# STM32H563 register map
File version: 1.6
CPU: CM33 r0p0, little endian, MPU, FPU, 4 interrupt priority bits
Registers are 32-bit, read-write, reset 0x0 unless marked. A register's access mark holds for its fields unless they carry their own. Offsets are from the block's base; [hi:lo] are bit positions.

## DCACHE — Data cache
Base 0x40031400
Same registers: SEC_DCACHE 0x50031400
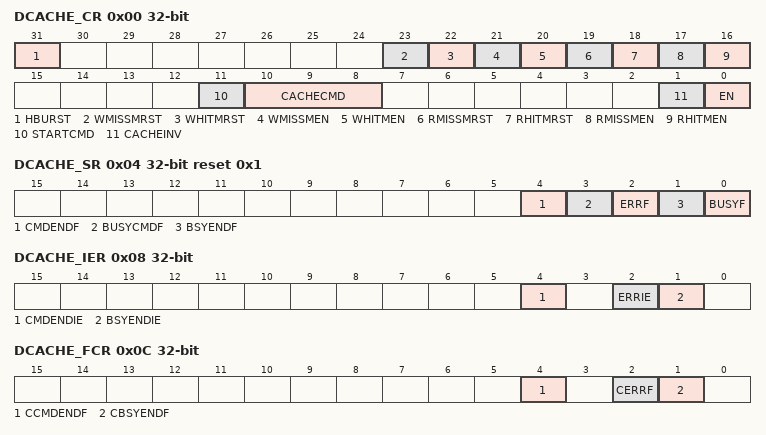
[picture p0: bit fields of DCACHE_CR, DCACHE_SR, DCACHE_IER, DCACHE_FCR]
0x00 DCACHE_CR access per field — DCACHE control register
  [31] HBURST rw — output burst type for cache master port read accesses Write access is always done in INCR burst type.
    0=WRAP; 1=INCR
  [23] WMISSMRST rw — write-miss monitor reset
    0=no effect; 1=reset cache write-miss monitor
  [22] WHITMRST rw — write-hit monitor reset
    0=no effect; 1=reset cache write-hit monitor
  [21] WMISSMEN rw — write-miss monitor enable
    0=cache write-miss monitor switched off. Stopping the monitor does not reset it.; 1=cache write-miss monitor enabled
  [20] WHITMEN rw — write-hit monitor enable
    0=cache write-hit monitor switched off. Stopping the monitor does not reset it.; 1=cache write-hit monitor enabled
  [19] RMISSMRST rw — read-miss monitor reset
    0=no effect; 1=reset cache read-miss monitor
  [18] RHITMRST rw — read-hit monitor reset
    0=no effect; 1=reset cache read-hit monitor
  [17] RMISSMEN rw — read-miss monitor enable
    0=cache read-miss monitor switched off. Stopping the monitor does not reset it.; 1=cache read-miss monitor enabled
  [16] RHITMEN rw — read-hit monitor enable
    0=cache read-hit monitor switched off. Stopping the monitor does not reset it.; 1=cache read-hit monitor enabled
  [11] STARTCMD wo — starts maintenance command (maintenance operation defined in CACHECMD). Can be set by software, only when EN = 1, BUSYCMDF = 0, BUSYF = 0 and CACHECMD = 0b001, 0b010 or 0b011. Cleared by hardware when the BUSYCMDF flag is set (during cache maintenance operation). Writing 0 has no effect.
    0=command operation (cache maintenance) finished; 1=start maintenance command (cache maintenance)
  [10:8] CACHECMD rw — cache command maintenance operation (cleans and/or invalidates an address range) Can be set and cleared by software, only when no maintenance command is ongoing (BUSYCMDF = 0). others: reserved
    0=no operation; 1=clean range; 2=invalidate range; 3=clean and invalidate range
  [1] CACHEINV wo — full cache invalidation Can be set by software, only when EN = 1. Cleared by hardware when the BUSYF flag is set (during full cache invalidation operation). Writing 0 has no effect.
    0=no effect; 1=invalidate entire cache (all cache lines valid bit = 0)
  [0] EN rw — enable
    0=cache disabled; 1=cache enabled
0x04 DCACHE_SR ro reset 0x1 — DCACHE status register
  [4] CMDENDF — command end flag Cleared by writing DCACHE_FCR.CCMDENDF = 1.
    0=cache busy or in idle; 1=CACHECMD command finished
  [3] BUSYCMDF — command busy flag
    0=cache not busy on a CACHECMD command; 1=cache busy on a CACHECMD command (clean and/or invalidate an address range)
  [2] ERRF — cache error flag Cleared by writing DCACHE_FCR.CERRF = 1.
    0=no error; 1=an error occurred during the operation (eviction or clean operation write-back error)
  [1] BSYENDF — full invalidate busy end flag Cleared by writing DCACHE_FCR.CBSYENDF = 1.
    0=cache busy or in idle; 1=full invalidate CACHEINV operation finished
  [0] BUSYF — full invalidate busy flag
    0=cache not busy on a CACHEINV operation; 1=cache executing a full invalidate CACHEINV operation
0x08 DCACHE_IER — DCACHE interrupt enable register
  [4] CMDENDIE — interrupt enable on command end Set by software to enable an interrupt generation at the end of a cache command (clean and/or invalidate an address range)
    0=interrupt disabled on command end; 1=interrupt enabled on command end
  [2] ERRIE — interrupt enable on cache error Set by software to enable an interrupt generation in case of cache functional error (eviction or clean operation write-back error)
    0=interrupt disabled on error; 1=interrupt enabled on error
  [1] BSYENDIE — interrupt enable on busy end Set by SW to enable an interrupt generation at the end of a cache full invalidate operation.
    0=Interrupt disabled on busy end; 1=Interrupt enabled on busy end
0x0C DCACHE_FCR wo — DCACHE flag clear register
  [4] CCMDENDF — clear command end flag Set by software.
    0=no effect; 1=clears CMDENDF flag in DCACHE_SR
  [2] CERRF — clear cache error flag Set by software.
    0=no effect; 1=clears ERRF flag in DCACHE_SR
  [1] CBSYENDF — clear full invalidate busy end flag Set by software.
    0=no effect; 1=clears BSYENDF flag in DCACHE_SR
0x10 DCACHE_RHMONR ro — DCACHE read-hit monitor register
  [31:0] RHITMON — cache read-hit monitor counter
0x14 DCACHE_RMMONR ro — DCACHE read-miss monitor register
  [15:0] RMISSMON — cache read-miss monitor counter
0x20 DCACHE_WHMONR ro — DCACHE write-hit monitor register
  [31:0] WHITMON — cache write-hit monitor counter
0x24 DCACHE_WMMONR ro — DCACHE write-miss monitor register
  [15:0] WMISSMON — cache write-miss monitor counter
0x28 DCACHE_CMDRSADDRR — DCACHE command range start address register
  [31:4] CMDSTARTADDR — start address of range to which the cache maintenance command specified in DCACHE_CR.CACHECMD field applies This register must be set before DCACHE_CR.CACHECMD is written. .
0x2C DCACHE_CMDREADDRR — DCACHE command range end address register
  [31:4] CMDENDADDR — end address of range to which the cache maintenance command specified in DCACHE_CR.CACHECMD field applies This register must be set before DCACHE_CR.CACHECMD is written.

## Notices in the file
Copyright (c) 2025 STMicroelectronics.
SPDX-License-Identifier: Apache-2.0
Licensed under the Apache License, Version 2.0 (the "License");
you may not use this file except in compliance with the License.
You may obtain a copy of the License at
http://www.apache.org/licenses/LICENSE-2.0
Unless required by applicable law or agreed to in writing, software
distributed under the License is distributed on an "AS IS" BASIS,
WITHOUT WARRANTIES OR CONDITIONS OF ANY KIND, either express or implied.
See the License for the specific language governing permissions and
limitations under the License.
